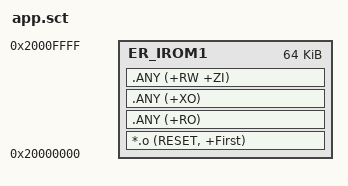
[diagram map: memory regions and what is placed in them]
; *************************************************************
; *** Scatter-Loading Description File generated by uVision ***
; *************************************************************

LR_IROM1 0x800B000 0x75000 {    ; load region size_region   75000
  ER_IROM1 0x20000000 0x00010000  {  ; load address = execution address  75000
   *.o (RESET, +First)
;   *(InRoot$$Sections)
   .ANY (+RO)
   .ANY (+XO)
   .ANY (+RW +ZI)
  }
;  RW_IRAM1 0x20000000 0x00010000  {  ; RW data
;   .ANY (+RW +ZI)
  ;}
}

